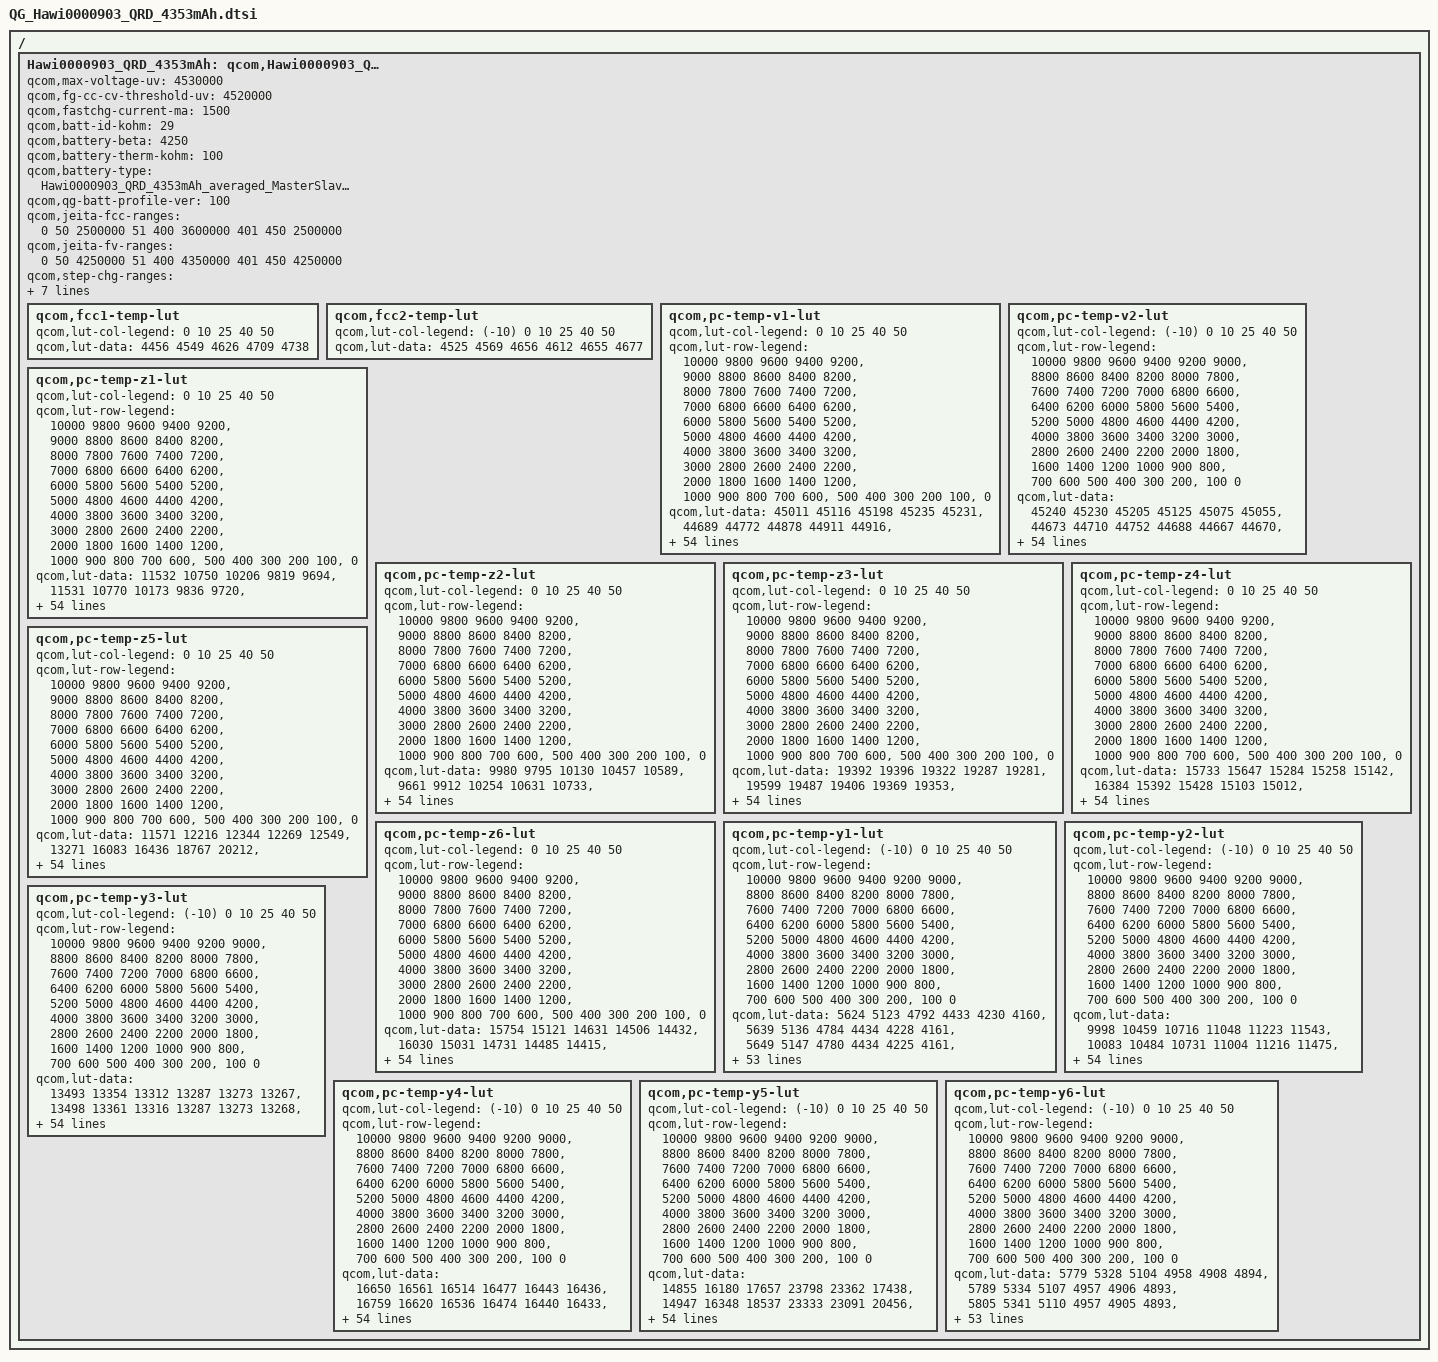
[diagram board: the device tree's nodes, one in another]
/* Copyright (c) 2018, The Linux Foundation. All rights reserved.
 *
 * This program is free software; you can redistribute it and/or modify
 * it under the terms of the GNU General Public License version 2 and
 * only version 2 as published by the Free Software Foundation.
 *
 * This program is distributed in the hope that it will be useful,
 * but WITHOUT ANY WARRANTY; without even the implied warranty of
 * MERCHANTABILITY or FITNESS FOR A PARTICULAR PURPOSE.  See the
 * GNU General Public License for more details.
 */

/ {
Hawi0000903_QRD_4353mAh: qcom,Hawi0000903_QRD_4353mAh {
    /* Hawi0000903_QRD_4353mAh_averaged_MasterSlave_Sept23rd2025 */
    qcom,max-voltage-uv = <4530000>;
    qcom,fg-cc-cv-threshold-uv = <4520000>;
    qcom,fastchg-current-ma = <1500>;
    qcom,batt-id-kohm = <29>;
    qcom,battery-beta = <4250>;
    qcom,battery-therm-kohm = <100>;
    qcom,battery-type = "Hawi0000903_QRD_4353mAh_averaged_MasterSlave_Sept23rd2025";
    qcom,qg-batt-profile-ver = <100>;

	qcom,jeita-fcc-ranges = <0  50   2500000
				51  400  3600000
				401 450  2500000>;
	qcom,jeita-fv-ranges = <0   50   4250000
				51  400  4350000
				401 450  4250000>;
	qcom,step-chg-ranges = <3600000  3800000  5400000
				3800001  4300000  3600000
				4300001  4350000  2500000>;
	qcom,ocv-based-step-chg;

	/* COOL = 5 DegC, WARM = 40 DegC */
	qcom,jeita-soft-thresholds = <0x5314 0x25e3>;
	/* COLD = 0 DegC, HOT = 45 DegC */
	qcom,jeita-hard-thresholds = <0x58cd 0x20b8>;
	/* COOL hys = 8 DegC, WARM hys = 37 DegC */
	qcom,jeita-soft-hys-thresholds = <0x4f5e 0x2943>;
	qcom,jeita-soft-fcc-ua = <2500000 2500000>;
	qcom,jeita-soft-fv-uv = <4250000 4250000>;

	qcom,fcc1-temp-lut {
		qcom,lut-col-legend = <0 10 25 40 50>;
		qcom,lut-data = <4456 4549 4626 4709 4738>;
	};

	qcom,fcc2-temp-lut {
		qcom,lut-col-legend = <(-10) 0 10 25 40 50>;
		qcom,lut-data = <4525 4569 4656 4612 4655 4677>;
	};

	qcom,pc-temp-v1-lut {
		qcom,lut-col-legend = <0 10 25 40 50>;
		qcom,lut-row-legend = <10000 9800 9600 9400 9200>,
			<9000 8800 8600 8400 8200>,
			<8000 7800 7600 7400 7200>,
			<7000 6800 6600 6400 6200>,
			<6000 5800 5600 5400 5200>,
			<5000 4800 4600 4400 4200>,
			<4000 3800 3600 3400 3200>,
			<3000 2800 2600 2400 2200>,
			<2000 1800 1600 1400 1200>,
			<1000 900 800 700 600>,
			<500 400 300 200 100>,
			<0>;
		qcom,lut-data = <45011 45116 45198 45235 45231>,
			<44689 44772 44878 44911 44916>,
			<44435 44485 44623 44671 44683>,
			<44222 44264 44346 44436 44464>,
			<44007 44062 44110 44174 44203>,
			<43793 43850 43890 43942 43974>,
			<43573 43630 43662 43715 43753>,
			<43341 43403 43434 43485 43530>,
			<43101 43164 43199 43255 43304>,
			<42855 42918 42953 43014 43068>,
			<42602 42667 42703 42765 42821>,
			<42351 42413 42452 42514 42569>,
			<42104 42162 42199 42258 42315>,
			<41861 41916 41950 42004 42060>,
			<41624 41674 41703 41754 41810>,
			<41391 41438 41463 41509 41566>,
			<41163 41206 41233 41273 41326>,
			<40943 40972 41001 41047 41095>,
			<40725 40742 40756 40792 40844>,
			<40507 40490 40502 40490 40540>,
			<40289 40170 40234 40202 40238>,
			<40053 39857 39947 39957 39994>,
			<39771 39654 39708 39736 39780>,
			<39513 39502 39525 39546 39587>,
			<39330 39354 39364 39376 39412>,
			<39181 39203 39210 39217 39248>,
			<39054 39062 39068 39068 39097>,
			<38945 38931 38935 38928 38952>,
			<38846 38809 38812 38803 38816>,
			<38750 38695 38690 38677 38679>,
			<38660 38590 38571 38527 38518>,
			<38574 38482 38443 38359 38337>,
			<38494 38374 38285 38188 38157>,
			<38413 38257 38103 38014 37979>,
			<38335 38111 37923 37833 37795>,
			<38248 37940 37739 37635 37591>,
			<38130 37767 37560 37445 37393>,
			<37971 37588 37367 37297 37246>,
			<37798 37421 37208 37160 37120>,
			<37599 37268 37139 36981 36945>,
			<37405 37135 37098 36751 36696>,
			<37262 37064 36966 36506 36431>,
			<37142 37019 36508 36256 36165>,
			<37038 36605 36128 35955 35858>,
			<36702 35798 35786 35570 35480>,
			<35780 35274 35254 35036 34944>,
			<35422 34932 34908 34675 34584>,
			<35035 34567 34529 34291 34196>,
			<34627 34209 34145 33926 33825>,
			<34216 33877 33797 33595 33493>,
			<33785 33561 33482 33286 33188>,
			<33383 33236 33167 32979 32883>,
			<32989 32848 32794 32617 32527>,
			<32440 32224 32241 32033 31964>,
			<31189 30791 30969 30673 30653>,
			<30000 30000 30000 30000 30000>;
	};

	qcom,pc-temp-v2-lut {
		qcom,lut-col-legend = <(-10) 0 10 25 40 50>;
		qcom,lut-row-legend = <10000 9800 9600 9400 9200 9000>,
			<8800 8600 8400 8200 8000 7800>,
			<7600 7400 7200 7000 6800 6600>,
			<6400 6200 6000 5800 5600 5400>,
			<5200 5000 4800 4600 4400 4200>,
			<4000 3800 3600 3400 3200 3000>,
			<2800 2600 2400 2200 2000 1800>,
			<1600 1400 1200 1000 900 800>,
			<700 600 500 400 300 200>,
			<100 0>;
		qcom,lut-data = <45240 45230 45205 45125 45075 45055>,
			<44673 44710 44752 44688 44667 44670>,
			<44224 44299 44395 44334 44334 44354>,
			<43928 44032 44162 44089 44096 44126>,
			<43721 43845 43995 43909 43917 43953>,
			<43517 43654 43814 43718 43724 43764>,
			<43302 43447 43613 43509 43514 43557>,
			<43084 43234 43403 43291 43295 43340>,
			<42857 43012 43180 43062 43064 43112>,
			<42622 42781 42947 42823 42823 42874>,
			<42372 42547 42710 42577 42578 42629>,
			<42104 42311 42466 42325 42327 42377>,
			<41823 42050 42200 42070 42074 42125>,
			<41524 41741 41908 41824 41827 41880>,
			<41218 41414 41597 41560 41557 41608>,
			<40924 41099 41255 41225 41208 41254>,
			<40638 40792 40911 40854 40839 40888>,
			<40366 40511 40625 40554 40556 40611>,
			<40109 40257 40375 40307 40321 40379>,
			<39865 40021 40143 40082 40103 40160>,
			<39636 39800 39925 39876 39899 39953>,
			<39422 39593 39718 39684 39705 39755>,
			<39222 39397 39521 39499 39525 39574>,
			<39037 39211 39328 39322 39346 39388>,
			<38855 39028 39135 39137 39135 39152>,
			<38672 38852 38943 38944 38892 38881>,
			<38483 38671 38733 38738 38656 38634>,
			<38260 38473 38499 38514 38430 38412>,
			<37995 38260 38250 38275 38202 38187>,
			<37771 38018 37966 38018 37949 37933>,
			<37608 37725 37685 37746 37701 37692>,
			<37463 37474 37495 37541 37522 37521>,
			<37322 37313 37356 37404 37385 37381>,
			<37185 37166 37185 37256 37222 37212>,
			<36996 36955 36952 37041 37012 37005>,
			<36702 36684 36696 36784 36773 36771>,
			<36384 36415 36444 36519 36511 36512>,
			<36104 36163 36176 36238 36221 36223>,
			<35822 35892 35877 35934 35907 35903>,
			<35497 35569 35548 35593 35566 35562>,
			<35128 35216 35217 35254 35237 35235>,
			<34757 34857 34875 34923 34906 34904>,
			<34376 34476 34506 34564 34526 34531>,
			<33960 34044 34075 34132 34109 34128>,
			<33482 33559 33584 33655 33636 33666>,
			<32987 33035 33051 33127 33107 33139>,
			<32729 32754 32778 32863 32844 32872>,
			<32467 32484 32516 32606 32584 32614>,
			<32198 32220 32261 32356 32327 32355>,
			<31922 31938 31991 32101 32055 32080>,
			<31606 31620 31683 31810 31738 31773>,
			<31221 31218 31301 31440 31321 31376>,
			<30734 30631 30721 30905 30702 30793>,
			<30175 29749 29806 30112 29747 29889>,
			<29208 28511 28467 29046 28527 28670>,
			<28078 27111 26715 27746 26965 27102>;
	};

	qcom,pc-temp-z1-lut {
		qcom,lut-col-legend = <0 10 25 40 50>;
		qcom,lut-row-legend = <10000 9800 9600 9400 9200>,
			<9000 8800 8600 8400 8200>,
			<8000 7800 7600 7400 7200>,
			<7000 6800 6600 6400 6200>,
			<6000 5800 5600 5400 5200>,
			<5000 4800 4600 4400 4200>,
			<4000 3800 3600 3400 3200>,
			<3000 2800 2600 2400 2200>,
			<2000 1800 1600 1400 1200>,
			<1000 900 800 700 600>,
			<500 400 300 200 100>,
			<0>;
		qcom,lut-data = <11532 10750 10206 9819 9694>,
			<11531 10770 10173 9836 9720>,
			<11542 10751 10172 9827 9716>,
			<11526 10740 10141 9820 9710>,
			<11502 10730 10135 9808 9706>,
			<11462 10724 10132 9804 9702>,
			<11419 10710 10130 9801 9699>,
			<11379 10700 10128 9797 9697>,
			<11343 10690 10126 9794 9695>,
			<11324 10676 10121 9791 9693>,
			<11310 10672 10115 9788 9690>,
			<11305 10669 10111 9786 9687>,
			<11311 10667 10108 9784 9686>,
			<11322 10662 10107 9782 9685>,
			<11334 10659 10107 9779 9684>,
			<11357 10661 10108 9777 9683>,
			<11367 10665 10106 9777 9682>,
			<11355 10667 10106 9778 9681>,
			<11341 10669 10109 9778 9681>,
			<11345 10671 10112 9779 9682>,
			<11358 10684 10115 9780 9683>,
			<11367 10700 10118 9781 9683>,
			<11369 10704 10121 9782 9683>,
			<11372 10704 10124 9784 9684>,
			<11379 10709 10128 9786 9685>,
			<11389 10732 10132 9788 9686>,
			<11402 10750 10136 9789 9688>,
			<11423 10748 10141 9791 9689>,
			<11441 10742 10148 9793 9691>,
			<11453 10743 10156 9797 9693>,
			<11462 10751 10166 9801 9696>,
			<11470 10761 10175 9806 9699>,
			<11484 10776 10181 9809 9701>,
			<11491 10793 10187 9813 9703>,
			<11507 10804 10192 9817 9705>,
			<11528 10813 10197 9820 9708>,
			<11532 10826 10203 9824 9711>,
			<11538 10844 10209 9828 9713>,
			<11549 10860 10215 9833 9715>,
			<11589 10868 10222 9835 9717>,
			<11630 10875 10230 9836 9718>,
			<11636 10889 10237 9838 9721>,
			<11632 10913 10243 9842 9724>,
			<11653 10928 10252 9850 9728>,
			<11677 10949 10271 9863 9732>,
			<11719 11011 10310 9867 9737>,
			<11720 11031 10299 9871 9739>,
			<11732 11030 10303 9874 9742>,
			<11766 11018 10311 9876 9744>,
			<11752 11016 10314 9878 9745>,
			<11775 11026 10311 9879 9748>,
			<11742 11022 10310 9881 9750>,
			<11759 11042 10316 9884 9752>,
			<11809 11031 10322 9890 9757>,
			<11809 11031 10322 9890 9757>,
			<11809 11031 10322 9890 9757>;
	};

	qcom,pc-temp-z2-lut {
		qcom,lut-col-legend = <0 10 25 40 50>;
		qcom,lut-row-legend = <10000 9800 9600 9400 9200>,
			<9000 8800 8600 8400 8200>,
			<8000 7800 7600 7400 7200>,
			<7000 6800 6600 6400 6200>,
			<6000 5800 5600 5400 5200>,
			<5000 4800 4600 4400 4200>,
			<4000 3800 3600 3400 3200>,
			<3000 2800 2600 2400 2200>,
			<2000 1800 1600 1400 1200>,
			<1000 900 800 700 600>,
			<500 400 300 200 100>,
			<0>;
		qcom,lut-data = <9980 9795 10130 10457 10589>,
			<9661 9912 10254 10631 10733>,
			<9741 10074 10310 10434 10550>,
			<9877 10104 10469 10447 10568>,
			<9917 10053 10398 10415 10588>,
			<9911 10033 10286 10417 10596>,
			<9902 10029 10251 10422 10630>,
			<9888 10024 10235 10430 10640>,
			<9868 10013 10227 10441 10633>,
			<9862 10002 10223 10445 10626>,
			<9861 10004 10218 10447 10617>,
			<9860 10012 10201 10449 10612>,
			<9857 10016 10178 10451 10613>,
			<9854 10010 10176 10452 10616>,
			<9852 10004 10182 10454 10620>,
			<9849 10008 10184 10459 10625>,
			<9847 10016 10183 10462 10629>,
			<9849 10025 10181 10465 10633>,
			<9852 10035 10187 10464 10634>,
			<9857 10046 10201 10445 10603>,
			<9866 10065 10198 10424 10567>,
			<9880 10082 10174 10397 10555>,
			<9912 10077 10162 10372 10548>,
			<9937 10060 10160 10382 10546>,
			<9934 10053 10158 10416 10550>,
			<9925 10052 10168 10430 10560>,
			<9919 10053 10191 10431 10593>,
			<9916 10060 10207 10435 10631>,
			<9914 10073 10221 10463 10663>,
			<9915 10086 10233 10499 10690>,
			<9918 10098 10243 10516 10702>,
			<9923 10111 10256 10528 10709>,
			<9932 10125 10298 10542 10723>,
			<9944 10141 10370 10559 10758>,
			<9959 10166 10416 10575 10779>,
			<9975 10199 10444 10592 10778>,
			<9988 10218 10468 10606 10773>,
			<9998 10227 10507 10612 10771>,
			<10009 10232 10538 10613 10766>,
			<10022 10235 10504 10599 11113>,
			<10032 10236 10400 10558 12928>,
			<10015 10222 10315 10632 13766>,
			<9971 10183 10239 12053 12539>,
			<9949 10252 10556 12484 11725>,
			<9924 10347 11288 12048 11490>,
			<9904 10309 10696 12005 11516>,
			<9904 10321 11191 11711 11193>,
			<9895 10332 12031 11376 10862>,
			<9918 10357 12759 11024 10563>,
			<9949 10351 12756 10734 10325>,
			<10016 10301 12404 10478 10140>,
			<10094 10272 11887 10253 9980>,
			<10074 10262 11231 10033 9847>,
			<10072 10380 10503 9783 9694>,
			<10072 10380 10503 9783 9694>,
			<10072 10380 10503 9783 9694>;
	};

	qcom,pc-temp-z3-lut {
		qcom,lut-col-legend = <0 10 25 40 50>;
		qcom,lut-row-legend = <10000 9800 9600 9400 9200>,
			<9000 8800 8600 8400 8200>,
			<8000 7800 7600 7400 7200>,
			<7000 6800 6600 6400 6200>,
			<6000 5800 5600 5400 5200>,
			<5000 4800 4600 4400 4200>,
			<4000 3800 3600 3400 3200>,
			<3000 2800 2600 2400 2200>,
			<2000 1800 1600 1400 1200>,
			<1000 900 800 700 600>,
			<500 400 300 200 100>,
			<0>;
		qcom,lut-data = <19392 19396 19322 19287 19281>,
			<19599 19487 19406 19369 19353>,
			<19654 19533 19407 19362 19342>,
			<19682 19545 19440 19342 19327>,
			<19688 19543 19431 19354 19328>,
			<19686 19540 19415 19350 19329>,
			<19685 19530 19406 19344 19324>,
			<19680 19522 19400 19340 19320>,
			<19671 19516 19395 19337 19315>,
			<19664 19511 19391 19334 19314>,
			<19657 19508 19388 19331 19314>,
			<19651 19504 19383 19329 19314>,
			<19645 19500 19379 19328 19314>,
			<19640 19494 19377 19327 19313>,
			<19635 19488 19376 19327 19311>,
			<19629 19484 19375 19326 19306>,
			<19623 19480 19374 19326 19305>,
			<19616 19478 19373 19324 19306>,
			<19610 19477 19376 19325 19308>,
			<19608 19476 19381 19335 19317>,
			<19606 19483 19382 19341 19325>,
			<19607 19491 19381 19340 19324>,
			<19620 19490 19382 19339 19320>,
			<19632 19484 19383 19336 19318>,
			<19630 19482 19385 19332 19316>,
			<19625 19482 19383 19330 19314>,
			<19620 19482 19380 19329 19312>,
			<19614 19480 19377 19329 19310>,
			<19608 19475 19375 19327 19310>,
			<19603 19471 19374 19325 19310>,
			<19598 19467 19374 19326 19312>,
			<19594 19465 19374 19330 19316>,
			<19590 19465 19375 19330 19317>,
			<19586 19465 19377 19329 19316>,
			<19583 19463 19378 19328 19315>,
			<19579 19461 19380 19330 19316>,
			<19575 19461 19382 19331 19318>,
			<19570 19462 19383 19331 19316>,
			<19568 19463 19385 19330 19312>,
			<19569 19462 19382 19328 19321>,
			<19570 19459 19370 19324 19379>,
			<19566 19453 19355 19330 19428>,
			<19553 19441 19331 19461 19459>,
			<19544 19446 19349 19509 19468>,
			<19539 19459 19402 19503 19464>,
			<19542 19465 19396 19443 19431>,
			<19547 19470 19412 19484 19455>,
			<19555 19475 19442 19535 19490>,
			<19563 19481 19509 19593 19533>,
			<19572 19482 19583 19660 19578>,
			<19589 19482 19668 19731 19622>,
			<19610 19485 19768 19787 19657>,
			<19627 19495 19902 19815 19670>,
			<19654 19532 19998 19821 19657>,
			<19654 19532 19998 19821 19657>,
			<19654 19532 19998 19821 19657>;
	};

	qcom,pc-temp-z4-lut {
		qcom,lut-col-legend = <0 10 25 40 50>;
		qcom,lut-row-legend = <10000 9800 9600 9400 9200>,
			<9000 8800 8600 8400 8200>,
			<8000 7800 7600 7400 7200>,
			<7000 6800 6600 6400 6200>,
			<6000 5800 5600 5400 5200>,
			<5000 4800 4600 4400 4200>,
			<4000 3800 3600 3400 3200>,
			<3000 2800 2600 2400 2200>,
			<2000 1800 1600 1400 1200>,
			<1000 900 800 700 600>,
			<500 400 300 200 100>,
			<0>;
		qcom,lut-data = <15733 15647 15284 15258 15142>,
			<16384 15392 15428 15103 15012>,
			<16407 15344 14884 14811 14764>,
			<15931 15358 14977 14699 14679>,
			<15600 15111 14924 14770 14705>,
			<15386 14969 14835 14750 14711>,
			<15223 14888 14795 14724 14694>,
			<15099 14841 14772 14708 14683>,
			<15003 14819 14752 14695 14676>,
			<14943 14804 14735 14685 14669>,
			<14902 14790 14722 14676 14661>,
			<14874 14777 14713 14668 14654>,
			<14855 14767 14705 14661 14647>,
			<14842 14758 14698 14655 14642>,
			<14829 14751 14691 14650 14639>,
			<14818 14743 14686 14646 14637>,
			<14810 14737 14681 14644 14636>,
			<14802 14736 14678 14643 14637>,
			<14797 14739 14686 14648 14638>,
			<14797 14746 14705 14691 14665>,
			<14801 14814 14730 14722 14692>,
			<14811 14895 14768 14711 14687>,
			<14877 14889 14781 14693 14672>,
			<14935 14845 14754 14683 14665>,
			<14937 14812 14724 14675 14659>,
			<14934 14790 14714 14671 14657>,
			<14929 14775 14707 14668 14655>,
			<14908 14769 14704 14667 14655>,
			<14886 14765 14702 14668 14658>,
			<14871 14765 14702 14671 14664>,
			<14859 14767 14709 14682 14676>,
			<14851 14770 14723 14707 14695>,
			<14845 14784 14752 14726 14711>,
			<14843 14810 14801 14740 14722>,
			<14845 14847 14842 14757 14733>,
			<14850 14902 14880 14782 14748>,
			<14868 14948 14903 14800 14759>,
			<14910 14990 14913 14784 14748>,
			<14928 15011 14918 14751 14722>,
			<14928 14981 14878 14791 14734>,
			<14928 14914 14777 14988 14835>,
			<14887 14839 14820 15071 14898>,
			<14797 14756 15268 15038 14913>,
			<14762 15062 15363 15014 14916>,
			<14843 15461 15305 15000 14906>,
			<15184 15281 15127 14948 14875>,
			<15290 15374 15195 14968 14886>,
			<15424 15489 15273 15000 14905>,
			<15586 15625 15335 15035 14921>,
			<15757 15762 15382 15044 14930>,
			<15950 15884 15393 15045 14935>,
			<16098 15993 15374 15045 14943>,
			<16193 16067 15297 15035 14942>,
			<16280 16188 15219 14994 14921>,
			<16280 16188 15219 14994 14921>,
			<16280 16188 15219 14994 14921>;
	};

	qcom,pc-temp-z5-lut {
		qcom,lut-col-legend = <0 10 25 40 50>;
		qcom,lut-row-legend = <10000 9800 9600 9400 9200>,
			<9000 8800 8600 8400 8200>,
			<8000 7800 7600 7400 7200>,
			<7000 6800 6600 6400 6200>,
			<6000 5800 5600 5400 5200>,
			<5000 4800 4600 4400 4200>,
			<4000 3800 3600 3400 3200>,
			<3000 2800 2600 2400 2200>,
			<2000 1800 1600 1400 1200>,
			<1000 900 800 700 600>,
			<500 400 300 200 100>,
			<0>;
		qcom,lut-data = <11571 12216 12344 12269 12549>,
			<13271 16083 16436 18767 20212>,
			<13786 17151 23914 25834 28811>,
			<14668 16504 18520 28974 30260>,
			<15498 17785 19125 20658 24170>,
			<16247 19068 20203 20989 22773>,
			<17070 20578 20550 21411 22941>,
			<18137 21583 20741 21699 22766>,
			<19340 21911 20955 21930 22113>,
			<20399 22144 21298 21925 21943>,
			<21414 22574 21504 21765 22749>,
			<22198 23255 21389 21722 23832>,
			<22684 23651 21212 22161 25056>,
			<23088 23790 21362 22837 26049>,
			<23597 23909 22102 23743 25425>,
			<24192 24251 22854 24817 23637>,
			<24664 24902 23491 25609 23495>,
			<25069 25662 24336 26302 26288>,
			<25562 26661 26549 26627 28076>,
			<26253 27642 29272 26163 26257>,
			<27342 28711 28285 25454 23655>,
			<29246 29508 22368 23593 22532>,
			<34786 28434 19781 21564 21658>,
			<39174 25101 21416 21755 21828>,
			<37845 24050 23688 22955 23236>,
			<34383 25866 25337 24341 24495>,
			<32235 28144 26858 26522 25275>,
			<30806 29702 28171 28124 26127>,
			<30134 31133 29289 28795 27747>,
			<30337 32490 30506 29316 29607>,
			<30851 33763 32201 30029 30301>,
			<31529 35085 33665 30733 30555>,
			<32622 36978 34354 30583 30095>,
			<33913 38437 34809 28946 27996>,
			<35796 38064 34945 27764 26722>,
			<37455 36791 34952 27264 26911>,
			<37685 36278 34861 27007 27213>,
			<37613 36255 33583 27713 27080>,
			<37569 36197 31879 29062 26580>,
			<37564 35527 31245 29095 26240>,
			<37547 34590 30856 28019 26023>,
			<37016 35176 29441 26628 25802>,
			<36026 37684 24171 23906 24604>,
			<39737 34449 20491 22400 23694>,
			<42627 30130 18967 21943 23109>,
			<41627 32613 21481 23058 24702>,
			<40534 29537 20041 22667 23616>,
			<39148 26983 19280 21705 22350>,
			<37384 24613 19179 20296 21213>,
			<35410 22221 18875 19926 20491>,
			<33761 20197 18472 19881 20180>,
			<31286 18457 18444 19560 19656>,
			<27249 16645 19250 18891 19084>,
			<22177 14467 18529 18542 19095>,
			<22177 14467 18529 18542 19095>,
			<22177 14467 18529 18542 19095>;
	};

	qcom,pc-temp-z6-lut {
		qcom,lut-col-legend = <0 10 25 40 50>;
		qcom,lut-row-legend = <10000 9800 9600 9400 9200>,
			<9000 8800 8600 8400 8200>,
			<8000 7800 7600 7400 7200>,
			<7000 6800 6600 6400 6200>,
			<6000 5800 5600 5400 5200>,
			<5000 4800 4600 4400 4200>,
			<4000 3800 3600 3400 3200>,
			<3000 2800 2600 2400 2200>,
			<2000 1800 1600 1400 1200>,
			<1000 900 800 700 600>,
			<500 400 300 200 100>,
			<0>;
		qcom,lut-data = <15754 15121 14631 14506 14432>,
			<16030 15031 14731 14485 14415>,
			<16013 14998 14492 14353 14301>,
			<15755 14995 14539 14292 14255>,
			<15560 14861 14510 14328 14266>,
			<15420 14777 14459 14316 14269>,
			<15305 14725 14434 14300 14259>,
			<15207 14691 14419 14291 14251>,
			<15126 14673 14406 14283 14245>,
			<15076 14659 14396 14276 14241>,
			<15040 14647 14387 14270 14237>,
			<15017 14636 14379 14265 14234>,
			<15003 14625 14373 14261 14230>,
			<14992 14616 14368 14258 14227>,
			<14983 14607 14364 14255 14224>,
			<14974 14600 14361 14253 14221>,
			<14967 14595 14358 14251 14220>,
			<14961 14594 14357 14251 14221>,
			<14958 14595 14361 14253 14222>,
			<14958 14599 14373 14277 14239>,
			<14962 14633 14386 14294 14256>,
			<14971 14674 14403 14289 14253>,
			<15010 14672 14409 14281 14245>,
			<15045 14654 14400 14275 14240>,
			<15050 14642 14388 14270 14237>,
			<15053 14636 14383 14267 14235>,
			<15053 14633 14379 14266 14233>,
			<15047 14631 14378 14265 14232>,
			<15042 14631 14377 14265 14233>,
			<15040 14631 14377 14265 14236>,
			<15039 14634 14382 14271 14242>,
			<15039 14639 14391 14284 14253>,
			<15042 14649 14407 14293 14260>,
			<15047 14666 14430 14300 14265>,
			<15055 14687 14450 14307 14269>,
			<15068 14716 14469 14319 14277>,
			<15085 14741 14482 14328 14283>,
			<15109 14766 14489 14322 14278>,
			<15130 14780 14493 14308 14265>,
			<15149 14770 14475 14320 14275>,
			<15160 14749 14428 14391 14349>,
			<15150 14725 14442 14455 14404>,
			<15130 14696 14617 14508 14429>,
			<15137 14841 14681 14521 14434>,
			<15210 15032 14689 14514 14430>,
			<15393 14982 14613 14462 14401>,
			<15453 15030 14653 14493 14419>,
			<15526 15088 14706 14535 14447>,
			<15607 15154 14771 14580 14478>,
			<15692 15217 14831 14620 14506>,
			<15792 15274 14882 14657 14533>,
			<15874 15329 14924 14687 14556>,
			<15932 15373 14961 14698 14564>,
			<15994 15452 14980 14689 14553>,
			<15994 15452 14980 14689 14553>,
			<15994 15452 14980 14689 14553>;
	};

	qcom,pc-temp-y1-lut {
		qcom,lut-col-legend = <(-10) 0 10 25 40 50>;
		qcom,lut-row-legend = <10000 9800 9600 9400 9200 9000>,
			<8800 8600 8400 8200 8000 7800>,
			<7600 7400 7200 7000 6800 6600>,
			<6400 6200 6000 5800 5600 5400>,
			<5200 5000 4800 4600 4400 4200>,
			<4000 3800 3600 3400 3200 3000>,
			<2800 2600 2400 2200 2000 1800>,
			<1600 1400 1200 1000 900 800>,
			<700 600 500 400 300 200>,
			<100 0>;
		qcom,lut-data = <5624 5123 4792 4433 4230 4160>,
			<5639 5136 4784 4434 4228 4161>,
			<5649 5147 4780 4434 4225 4161>,
			<5656 5155 4778 4433 4222 4160>,
			<5660 5159 4778 4431 4219 4158>,
			<5662 5161 4779 4429 4217 4157>,
			<5661 5162 4782 4425 4214 4154>,
			<5659 5161 4784 4421 4212 4152>,
			<5661 5160 4780 4418 4210 4151>,
			<5665 5157 4773 4415 4208 4151>,
			<5668 5156 4769 4412 4206 4149>,
			<5670 5156 4765 4409 4204 4145>,
			<5673 5157 4764 4407 4202 4144>,
			<5682 5160 4763 4404 4200 4144>,
			<5694 5163 4762 4403 4199 4145>,
			<5696 5169 4762 4404 4199 4144>,
			<5689 5178 4762 4405 4198 4143>,
			<5686 5182 4761 4405 4198 4142>,
			<5695 5183 4760 4406 4197 4142>,
			<5704 5183 4760 4406 4197 4142>,
			<5712 5180 4761 4406 4198 4142>,
			<5722 5174 4762 4406 4198 4142>,
			<5723 5176 4762 4406 4199 4143>,
			<5703 5183 4762 4406 4200 4144>,
			<5686 5186 4761 4406 4200 4144>,
			<5686 5183 4761 4408 4200 4143>,
			<5692 5179 4760 4410 4200 4143>,
			<5690 5177 4758 4410 4200 4143>,
			<5680 5176 4756 4411 4201 4144>,
			<5674 5177 4763 4412 4202 4144>,
			<5677 5185 4773 4415 4204 4145>,
			<5680 5189 4772 4418 4205 4145>,
			<5680 5184 4765 4420 4206 4146>,
			<5678 5173 4762 4422 4206 4147>,
			<5671 5164 4767 4424 4207 4147>,
			<5648 5154 4771 4426 4208 4148>,
			<5633 5151 4772 4430 4210 4149>,
			<5633 5158 4775 4436 4213 4150>,
			<5636 5169 4783 4442 4216 4152>,
			<5645 5189 4801 4447 4219 4153>,
			<5677 5208 4814 4453 4222 4155>,
			<5701 5217 4832 4458 4225 4158>,
			<5737 5237 4861 4465 4230 4161>,
			<5853 5319 4876 4476 4235 4164>,
			<5927 5339 4889 4491 4240 4168>,
			<6022 5356 4926 4505 4249 4172>,
			<6056 5367 4950 4513 4251 4175>,
			<6129 5376 4948 4528 4257 4178>,
			<6167 5417 4976 4540 4264 4182>,
			<6252 5501 5001 4556 4273 4187>,
			<6299 5544 4994 4570 4288 4196>,
			<6346 5579 5024 4581 4308 4211>,
			<6340 5647 5073 4601 4332 4234>,
			<6452 5785 5123 4616 4366 4264>,
			<6452 5785 5123 4616 4366 4264>,
			<6452 5785 5123 4616 4366 4264>;
	};

	qcom,pc-temp-y2-lut {
		qcom,lut-col-legend = <(-10) 0 10 25 40 50>;
		qcom,lut-row-legend = <10000 9800 9600 9400 9200 9000>,
			<8800 8600 8400 8200 8000 7800>,
			<7600 7400 7200 7000 6800 6600>,
			<6400 6200 6000 5800 5600 5400>,
			<5200 5000 4800 4600 4400 4200>,
			<4000 3800 3600 3400 3200 3000>,
			<2800 2600 2400 2200 2000 1800>,
			<1600 1400 1200 1000 900 800>,
			<700 600 500 400 300 200>,
			<100 0>;
		qcom,lut-data = <9998 10459 10716 11048 11223 11543>,
			<10083 10484 10731 11004 11216 11475>,
			<10166 10514 10736 10950 11202 11408>,
			<10242 10544 10734 10898 11183 11346>,
			<10308 10568 10727 10857 11159 11294>,
			<10359 10581 10717 10838 11131 11258>,
			<10399 10587 10693 10830 11094 11232>,
			<10432 10593 10678 10826 11062 11207>,
			<10463 10608 10689 10822 11041 11163>,
			<10491 10633 10710 10814 11027 11126>,
			<10513 10671 10726 10819 11023 11124>,
			<10534 10737 10747 10843 11026 11128>,
			<10547 10770 10774 10873 11035 11135>,
			<10553 10759 10836 10938 11064 11152>,
			<10557 10742 10876 10989 11100 11179>,
			<10556 10726 10845 10975 11137 11249>,
			<10551 10705 10800 10944 11174 11330>,
			<10547 10699 10797 10932 11203 11358>,
			<10544 10701 10804 10928 11234 11372>,
			<10540 10705 10812 10926 11248 11392>,
			<10533 10714 10829 10946 11252 11426>,
			<10520 10728 10845 10976 11253 11453>,
			<10506 10737 10856 11002 11260 11467>,
			<10493 10747 10865 11028 11269 11476>,
			<10470 10754 10877 11034 11264 11475>,
			<10210 10761 10891 11022 11254 11472>,
			<9814 10767 10897 11011 11252 11468>,
			<9724 10762 10898 11004 11275 11460>,
			<9705 10744 10894 10997 11296 11465>,
			<9695 10718 10868 10994 11304 11505>,
			<9688 10668 10833 10997 11307 11546>,
			<9683 10640 10837 11005 11291 11489>,
			<9681 10647 10875 11029 11242 11350>,
			<9679 10666 10949 11071 11241 11352>,
			<9677 10736 11202 11291 11462 11568>,
			<9674 10896 11384 11576 11638 11692>,
			<9671 10952 11343 11581 11606 11690>,
			<9670 10930 11238 11444 11527 11683>,
			<9668 10887 11089 11277 11421 11608>,
			<9667 10757 10862 11062 11249 11444>,
			<9666 10547 10641 10852 11074 11265>,
			<9665 10339 10458 10664 10885 11071>,
			<9663 10114 10851 10509 10820 11028>,
			<9659 10286 10434 10524 10646 10904>,
			<9655 9964 10044 10289 10495 10838>,
			<9652 9923 9914 10078 10313 10635>,
			<9651 9899 9901 9987 10221 10510>,
			<9650 9860 9889 9926 10135 10414>,
			<9657 9814 9881 9897 10059 10333>,
			<9656 9764 9866 9884 10029 10263>,
			<9652 9719 9852 9869 10039 10256>,
			<9649 9678 9834 9871 10086 10295>,
			<9648 9653 9789 9908 10183 10390>,
			<9647 9648 9715 9931 10225 10489>,
			<9647 9648 9715 9931 10225 10489>,
			<9647 9648 9715 9931 10225 10489>;
	};

	qcom,pc-temp-y3-lut {
		qcom,lut-col-legend = <(-10) 0 10 25 40 50>;
		qcom,lut-row-legend = <10000 9800 9600 9400 9200 9000>,
			<8800 8600 8400 8200 8000 7800>,
			<7600 7400 7200 7000 6800 6600>,
			<6400 6200 6000 5800 5600 5400>,
			<5200 5000 4800 4600 4400 4200>,
			<4000 3800 3600 3400 3200 3000>,
			<2800 2600 2400 2200 2000 1800>,
			<1600 1400 1200 1000 900 800>,
			<700 600 500 400 300 200>,
			<100 0>;
		qcom,lut-data = <13493 13354 13312 13287 13273 13267>,
			<13498 13361 13316 13287 13273 13268>,
			<13502 13368 13320 13288 13273 13269>,
			<13505 13375 13324 13289 13274 13270>,
			<13507 13380 13327 13289 13274 13271>,
			<13507 13384 13329 13290 13274 13271>,
			<13507 13386 13331 13290 13275 13272>,
			<13505 13387 13333 13291 13276 13272>,
			<13503 13387 13334 13292 13276 13273>,
			<13500 13386 13334 13294 13277 13274>,
			<13495 13386 13334 13295 13278 13274>,
			<13487 13387 13331 13295 13281 13274>,
			<13478 13388 13330 13295 13282 13275>,
			<13469 13383 13330 13295 13282 13277>,
			<13458 13374 13330 13295 13282 13278>,
			<13449 13368 13325 13294 13279 13275>,
			<13439 13361 13318 13290 13275 13271>,
			<13431 13357 13316 13288 13274 13271>,
			<13425 13354 13315 13286 13274 13271>,
			<13419 13352 13314 13286 13274 13271>,
			<13414 13351 13314 13286 13274 13271>,
			<13409 13350 13314 13287 13274 13271>,
			<13405 13348 13314 13288 13274 13271>,
			<13402 13347 13314 13288 13275 13272>,
			<13400 13345 13313 13288 13275 13271>,
			<13414 13344 13312 13288 13274 13269>,
			<13436 13343 13311 13287 13274 13269>,
			<13438 13341 13310 13286 13274 13271>,
			<13428 13338 13308 13285 13274 13272>,
			<13424 13334 13306 13285 13274 13272>,
			<13431 13330 13304 13285 13275 13272>,
			<13446 13328 13304 13285 13275 13272>,
			<13465 13330 13308 13287 13277 13274>,
			<13494 13335 13315 13291 13281 13277>,
			<13529 13344 13335 13306 13290 13285>,
			<13571 13362 13359 13329 13300 13291>,
			<13621 13384 13377 13347 13306 13295>,
			<13682 13410 13397 13362 13310 13299>,
			<13756 13444 13423 13378 13317 13303>,
			<13844 13491 13460 13397 13328 13309>,
			<13956 13555 13511 13420 13340 13317>,
			<14102 13641 13571 13447 13356 13327>,
			<14331 13751 13496 13475 13365 13338>,
			<14608 13646 13576 13471 13382 13348>,
			<15078 13865 13697 13514 13393 13352>,
			<15985 13986 13803 13561 13405 13352>,
			<16631 14051 13841 13585 13414 13355>,
			<17535 14207 13876 13610 13425 13362>,
			<18495 14469 13909 13637 13444 13374>,
			<20203 14903 13936 13664 13469 13393>,
			<23409 15770 13962 13686 13498 13425>,
			<29723 17910 14101 13710 13528 13462>,
			<47400 24501 14520 13716 13542 13488>,
			<65535 50759 15761 13712 13542 13495>,
			<65535 50759 15761 13712 13542 13495>,
			<65535 50759 15761 13712 13542 13495>;
	};

	qcom,pc-temp-y4-lut {
		qcom,lut-col-legend = <(-10) 0 10 25 40 50>;
		qcom,lut-row-legend = <10000 9800 9600 9400 9200 9000>,
			<8800 8600 8400 8200 8000 7800>,
			<7600 7400 7200 7000 6800 6600>,
			<6400 6200 6000 5800 5600 5400>,
			<5200 5000 4800 4600 4400 4200>,
			<4000 3800 3600 3400 3200 3000>,
			<2800 2600 2400 2200 2000 1800>,
			<1600 1400 1200 1000 900 800>,
			<700 600 500 400 300 200>,
			<100 0>;
		qcom,lut-data = <16650 16561 16514 16477 16443 16436>,
			<16759 16620 16536 16474 16440 16433>,
			<16877 16678 16559 16473 16437 16431>,
			<16991 16732 16581 16472 16436 16428>,
			<17083 16777 16599 16472 16435 16427>,
			<17139 16808 16609 16472 16435 16426>,
			<17172 16830 16615 16473 16435 16427>,
			<17194 16848 16621 16476 16437 16428>,
			<17206 16868 16631 16479 16439 16430>,
			<17214 16888 16646 16485 16444 16432>,
			<17214 16903 16672 16494 16448 16435>,
			<17199 16916 16709 16510 16454 16441>,
			<17175 16921 16719 16532 16465 16450>,
			<17141 16891 16708 16573 16495 16470>,
			<17097 16842 16688 16604 16515 16482>,
			<17058 16801 16638 16570 16490 16463>,
			<17023 16761 16578 16498 16451 16437>,
			<16989 16736 16560 16473 16440 16431>,
			<16954 16720 16552 16465 16436 16429>,
			<16924 16709 16550 16462 16435 16429>,
			<16900 16703 16554 16466 16440 16433>,
			<16879 16699 16561 16474 16448 16439>,
			<16864 16699 16569 16484 16461 16451>,
			<16853 16703 16578 16498 16475 16462>,
			<16841 16707 16585 16503 16471 16457>,
			<16820 16711 16591 16505 16455 16443>,
			<16792 16715 16592 16506 16450 16440>,
			<16749 16709 16579 16495 16451 16443>,
			<16679 16690 16559 16481 16454 16448>,
			<16649 16654 16530 16479 16460 16457>,
			<16649 16567 16502 16480 16469 16466>,
			<16652 16517 16508 16482 16476 16471>,
			<16674 16542 16553 16498 16483 16475>,
			<16739 16600 16625 16526 16499 16491>,
			<16818 16717 16792 16628 16562 16544>,
			<16930 16939 16940 16767 16615 16580>,
			<17067 17096 16992 16813 16628 16587>,
			<17241 17181 17030 16833 16636 16592>,
			<17436 17259 17087 16851 16647 16601>,
			<17590 17353 17158 16867 16659 16612>,
			<17716 17452 17229 16887 16675 16627>,
			<17801 17558 17295 16912 16695 16645>,
			<17922 17653 17223 16943 16720 16671>,
			<18306 17591 17294 16931 16742 16696>,
			<19006 17618 17325 16935 16755 16716>,
			<20236 17526 17268 16926 16749 16707>,
			<21214 17551 17223 16925 16748 16701>,
			<22641 17758 17205 16929 16758 16703>,
			<24500 18191 17208 16939 16779 16719>,
			<27248 18919 17252 16967 16817 16753>,
			<31603 20227 17313 17027 16878 16813>,
			<39531 22933 17531 17098 16972 16913>,
			<58228 30839 18375 17161 17085 17048>,
			<65535 63186 21171 17199 17141 17140>,
			<65535 63186 21171 17199 17141 17140>,
			<65535 63186 21171 17199 17141 17140>;
	};

	qcom,pc-temp-y5-lut {
		qcom,lut-col-legend = <(-10) 0 10 25 40 50>;
		qcom,lut-row-legend = <10000 9800 9600 9400 9200 9000>,
			<8800 8600 8400 8200 8000 7800>,
			<7600 7400 7200 7000 6800 6600>,
			<6400 6200 6000 5800 5600 5400>,
			<5200 5000 4800 4600 4400 4200>,
			<4000 3800 3600 3400 3200 3000>,
			<2800 2600 2400 2200 2000 1800>,
			<1600 1400 1200 1000 900 800>,
			<700 600 500 400 300 200>,
			<100 0>;
		qcom,lut-data = <14855 16180 17657 23798 23362 17438>,
			<14947 16348 18537 23333 23091 20456>,
			<15137 16470 18988 22735 22546 22561>,
			<15407 16550 19121 22028 21861 23870>,
			<15738 16593 19050 21240 21171 24500>,
			<16114 16598 18851 20372 20589 24477>,
			<16585 16520 18272 19248 19959 23256>,
			<17074 16444 17573 18381 19277 21958>,
			<17497 16412 16801 17940 18380 21243>,
			<17890 16384 16140 17506 17618 20561>,
			<18217 16598 16013 16925 17581 19414>,
			<18507 17621 15970 15812 17702 17936>,
			<18712 18322 16178 15371 17647 17346>,
			<18814 18529 18529 15816 16591 17149>,
			<18893 18652 20286 16649 15803 17085>,
			<19016 18595 19985 18570 17317 18268>,
			<19189 18420 19484 21226 19673 20095>,
			<19391 18371 19285 21490 20218 21036>,
			<19650 18467 19149 20118 20292 21689>,
			<19912 18612 19143 19394 20212 21599>,
			<20096 18798 19393 19720 19343 19926>,
			<20255 19029 19687 20171 18678 18838>,
			<20542 19227 19886 20397 18924 18833>,
			<21192 19418 20098 20599 19409 18854>,
			<21953 19688 20432 20967 19908 18868>,
			<22831 20239 21007 21924 20674 18901>,
			<23614 20991 21680 22480 21127 19252>,
			<22591 21932 22519 22385 21309 21138>,
			<17670 23077 23410 22260 21546 22595>,
			<14897 24033 24473 22967 22758 23030>,
			<14499 24981 25385 24999 24324 23249>,
			<14313 25405 24768 25450 23992 22851>,
			<14494 23272 21885 23151 21860 21715>,
			<15062 19780 19239 20311 19864 20333>,
			<15539 17662 16818 17637 17979 18363>,
			<16048 16017 15244 15424 16789 17439>,
			<16341 15147 14827 15134 16477 17467>,
			<15859 14749 14565 15138 16301 17500>,
			<14862 14436 14161 15087 16273 17252>,
			<14117 14077 13690 14755 16208 16931>,
			<13519 13742 13390 14449 15943 16590>,
			<13355 13444 13230 14233 15764 16284>,
			<13196 13151 14326 13993 16014 16924>,
			<12457 13692 13501 14566 16083 17106>,
			<11430 13262 12894 14352 16400 17548>,
			<10480 13446 12979 14140 16534 17968>,
			<10080 13100 13103 13915 16350 17822>,
			<9738 12281 13190 13688 15825 17550>,
			<9494 11408 13305 13670 15399 17054>,
			<9313 10672 13252 13730 15212 16439>,
			<9153 10096 13289 13659 15207 16334>,
			<9005 9603 13115 14030 15627 16390>,
			<8879 9144 11806 14924 16697 16887>,
			<8803 8873 10259 16127 17376 17635>,
			<8803 8873 10259 16127 17376 17635>,
			<8803 8873 10259 16127 17376 17635>;
	};

	qcom,pc-temp-y6-lut {
		qcom,lut-col-legend = <(-10) 0 10 25 40 50>;
		qcom,lut-row-legend = <10000 9800 9600 9400 9200 9000>,
			<8800 8600 8400 8200 8000 7800>,
			<7600 7400 7200 7000 6800 6600>,
			<6400 6200 6000 5800 5600 5400>,
			<5200 5000 4800 4600 4400 4200>,
			<4000 3800 3600 3400 3200 3000>,
			<2800 2600 2400 2200 2000 1800>,
			<1600 1400 1200 1000 900 800>,
			<700 600 500 400 300 200>,
			<100 0>;
		qcom,lut-data = <5779 5328 5104 4958 4908 4894>,
			<5789 5334 5107 4957 4906 4893>,
			<5805 5341 5110 4957 4905 4893>,
			<5822 5347 5111 4956 4905 4893>,
			<5835 5352 5113 4956 4904 4893>,
			<5841 5355 5113 4955 4904 4893>,
			<5842 5357 5112 4955 4905 4893>,
			<5843 5359 5111 4956 4906 4894>,
			<5842 5360 5112 4957 4907 4895>,
			<5839 5360 5113 4959 4908 4896>,
			<5834 5361 5117 4962 4910 4897>,
			<5823 5362 5123 4966 4913 4899>,
			<5809 5362 5124 4972 4917 4902>,
			<5792 5348 5119 4983 4926 4909>,
			<5774 5326 5110 4991 4931 4913>,
			<5757 5308 5091 4981 4922 4905>,
			<5741 5292 5068 4957 4907 4894>,
			<5728 5281 5060 4948 4904 4892>,
			<5716 5273 5056 4944 4902 4892>,
			<5707 5268 5056 4943 4902 4892>,
			<5702 5266 5056 4945 4903 4893>,
			<5699 5265 5058 4947 4905 4894>,
			<5699 5266 5060 4951 4910 4898>,
			<5701 5267 5062 4955 4914 4902>,
			<5704 5269 5064 4957 4913 4900>,
			<5706 5273 5066 4957 4908 4895>,
			<5707 5276 5066 4958 4906 4894>,
			<5704 5276 5062 4954 4906 4895>,
			<5687 5272 5056 4949 4907 4898>,
			<5679 5265 5048 4949 4909 4900>,
			<5693 5245 5040 4949 4912 4903>,
			<5718 5233 5043 4950 4915 4905>,
			<5751 5246 5060 4957 4918 4907>,
			<5799 5275 5088 4968 4926 4914>,
			<5856 5323 5151 5008 4950 4935>,
			<5924 5406 5214 5065 4974 4951>,
			<6006 5481 5246 5094 4981 4956>,
			<6107 5539 5274 5110 4987 4960>,
			<6227 5603 5313 5128 4996 4966>,
			<6354 5685 5365 5147 5008 4974>,
			<6493 5785 5428 5169 5021 4984>,
			<6652 5913 5498 5197 5039 4997>,
			<6905 6065 5432 5228 5053 5013>,
			<7352 5978 5520 5224 5073 5029>,
			<8074 6217 5638 5261 5087 5039>,
			<9286 6397 5735 5303 5097 5038>,
			<10147 6528 5776 5327 5106 5040>,
			<11307 6823 5824 5352 5121 5048>,
			<12847 7292 5884 5385 5145 5065>,
			<15103 8016 5961 5427 5180 5093>,
			<18691 9288 6064 5476 5230 5139>,
			<25350 11816 6347 5533 5294 5204>,
			<42730 18622 7103 5589 5354 5272>,
			<65535 45547 9155 5639 5400 5319>,
			<65535 45547 9155 5639 5400 5319>,
			<65535 45547 9155 5639 5400 5319>;
	};

};
};
